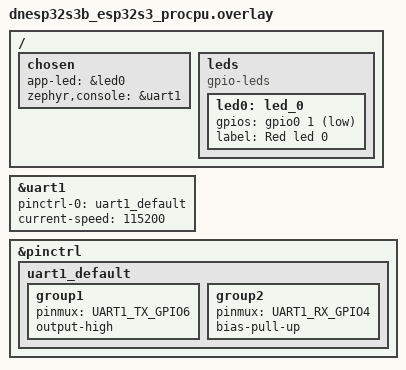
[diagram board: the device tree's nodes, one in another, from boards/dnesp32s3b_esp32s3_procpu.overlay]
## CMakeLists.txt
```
cmake_minimum_required(VERSION 3.20.0)

list(APPEND BOARD_ROOT ${CMAKE_CURRENT_SOURCE_DIR})

find_package(Zephyr REQUIRED HINTS $ENV{ZEPHYR_BASE})
project(0_base)
set(CMAKE_EXPORT_COMPILE_COMMANDS ON)

target_sources(app PRIVATE src/main.c)

target_compile_options(app PRIVATE
    -Wall
    -Wextra
)
```

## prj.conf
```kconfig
# 对应 -O2 或 -O3
# CONFIG_SPEED_OPTIMIZATIONS=y
# 对应 -Og
CONFIG_DEBUG_OPTIMIZATIONS=y
# 对应 -O0
CONFIG_NO_OPTIMIZATIONS=y
# 对应 -Os 体积优化
# CONFIG_SIZE_OPTIMIZATIONS=y 

# gdb线程感知
CONFIG_DEBUG_THREAD_INFO=y
```

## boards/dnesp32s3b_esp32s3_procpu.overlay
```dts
/{
	chosen{
		app-led = &led0;	
		zephyr,console = &uart1;
	};


	leds{
		compatible = "gpio-leds";

		led0: led_0{
			gpios = <&gpio0 1 GPIO_ACTIVE_LOW> ;
			label = "Red led 0";
		};
	};
};

// 可以在引用层的 `overlay` 文件的根节点之外
// 修改某一个已经存在的节点的既定属性。比如
// 我将 `gpio0` 给设置为禁止，再尝试运行
// `west build` 的时候就会编译错误，因为
// `GPIO_DT_SPEC_GET(LED_NODE, gpios)`
// 会找不到指定的设备
// &gpio0{
// 	status = "disabled";	
// };

// 在根节点外重新定义 `uart0`
// tx -> IO7
// rx -> IO5
// &uart0_default{
// 	group1 {
// 		pinmux = <UART0_TX_GPIO7>;	
// 		output-high;
// 	};
// 	group2 {
// 		pinmux = <UART0_RX_GPIO5>;
// 		bias-pull-up;	
// 	};
// };

// 或者，也可以尝试使用 `uart1/2`
// 不过需要将 `chosen` 节点中
// `zephyr,console` 设置为 `&uart1`
&uart1{
	status = "okay";
	pinctrl-0 = <&uart1_default>;
	pinctrl-names = "default";
	current-speed = <115200>;
};

&pinctrl{
	uart1_default: uart1_default{
		group1 {
			pinmux = <UART1_TX_GPIO6>;	
			output-high;
		};
		group2 {
			pinmux = <UART1_RX_GPIO4>;
			bias-pull-up;	
		};
	};
};
```

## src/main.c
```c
#include <zephyr/kernel.h>
#include <zephyr/drivers/gpio.h>

// 先访问到 `chosen` 节点下的 `app-led` 节点
#define LED_NODE DT_CHOSEN(app_led)

// 再通过这个节点来获取对应的 gpio
static const struct gpio_dt_spec app_led = GPIO_DT_SPEC_GET(LED_NODE, gpios);

int main(void)
{
    int err = 0;

    // 使用 `gpio_is_readt_dt` 来检查设备是否正确获取
    if (!gpio_is_ready_dt(&app_led))
    {
        printk("app_led is not ready yet\n");
        return -EIO;
    }

    // 然后使用 `gpio_pin_configure_dt` 来初始化这个设备
    err = gpio_pin_configure_dt(&app_led, GPIO_OUTPUT_ACTIVE);
    if (err < 0)
    {
        printk("app_led failed to configutration,err:%d\n", err);
        return -EIO;
    }

    bool led_status = false;

    while (1)
    {
        // 只要是结尾带 `_dt` 的，都可以直接传入一个设备
        // zephyr 会自动提取对应的属性，当然也可以使用
        // 不带有这个后缀的 API，只是需要自己处理设备
        // 的一些属性(e.g.port、pin)
        // gpio_pin_toggle(app_led.port, app_led.pin);
        gpio_pin_toggle_dt(&app_led);
        k_msleep(500);
        led_status = !led_status;

        if (led_status == false) printk("led turn off\n");
        else printk("led turn on\n");
    }

    return 0;
}
```
